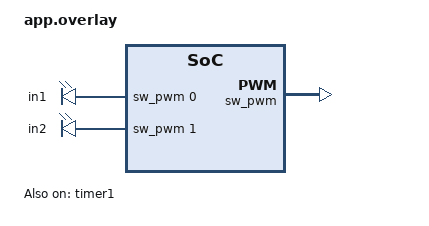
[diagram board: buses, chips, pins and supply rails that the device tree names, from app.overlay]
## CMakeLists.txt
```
# SPDX-License-Identifier: Apache-2.0

cmake_minimum_required(VERSION 3.20.0)
find_package(Zephyr REQUIRED HINTS $ENV{ZEPHYR_BASE})
project(lillabo)

target_sources(app PRIVATE src/main.c)
```

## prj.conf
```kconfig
CONFIG_GPIO=y
CONFIG_UART_CONSOLE=n
# LF clock source is set on the lfclk node in app.overlay; the RC calibration
# it used to need enabling for now defaults to y off that same property.

CONFIG_PWM=y

# From peripheral sample, reduced
CONFIG_BT=y
CONFIG_BT_SMP=y
CONFIG_BT_PERIPHERAL=y
CONFIG_BT_DIS=y
CONFIG_BT_DEVICE_NAME="LILLABOBT"
CONFIG_BT_DEVICE_APPEARANCE=833

# Added from MSLED
CONFIG_BT_RX_STACK_SIZE=1024
CONFIG_BT_HCI_TX_STACK_SIZE_WITH_PROMPT=y
CONFIG_BT_HCI_TX_STACK_SIZE=640
CONFIG_SYSTEM_WORKQUEUE_STACK_SIZE=512
CONFIG_IDLE_STACK_SIZE=64
CONFIG_MAIN_STACK_SIZE=640
CONFIG_ISR_STACK_SIZE=640

# Drivers and peripherals
CONFIG_I2C=n
CONFIG_WATCHDOG=n
CONFIG_SPI=n
CONFIG_SERIAL=n
CONFIG_ADC=n
CONFIG_PINCTRL=y

# Memory protection
CONFIG_THREAD_STACK_INFO=n
CONFIG_THREAD_CUSTOM_DATA=n
CONFIG_FPU=n

# Build
CONFIG_SIZE_OPTIMIZATIONS=y

# ARM
CONFIG_ARM_MPU=n

# Power management
CONFIG_PM=n
 
# Interrupts
CONFIG_DYNAMIC_INTERRUPTS=n
CONFIG_IRQ_OFFLOAD=n

# Disable features not needed
CONFIG_TIMESLICING=n
CONFIG_ASSERT=y

# Disable Bluetooth features not needed
# CONFIG_BT_DEBUG_NONE=y
CONFIG_BT_ASSERT=n
CONFIG_BT_DATA_LEN_UPDATE=n
CONFIG_BT_PHY_UPDATE=n
CONFIG_BT_GATT_CACHING=n
CONFIG_BT_GATT_SERVICE_CHANGED=n
CONFIG_BT_GAP_PERIPHERAL_PREF_PARAMS=n
# CONFIG_BT_HCI_VS_EXT=n

# Disable Bluetooth controller features not needed
CONFIG_BT_CTLR_PRIVACY=n
CONFIG_BT_CTLR_PHY_2M=n

# Reduce Bluetooth buffers
CONFIG_BT_BUF_EVT_DISCARDABLE_COUNT=1
CONFIG_BT_BUF_EVT_DISCARDABLE_SIZE=45
# CONFIG_BT_BUF_ACL_RX_COUNT=2
CONFIG_BT_BUF_EVT_RX_COUNT=2

CONFIG_BT_L2CAP_TX_BUF_COUNT=2
CONFIG_BT_CTLR_RX_BUFFERS=1
CONFIG_BT_BUF_ACL_TX_COUNT=1
CONFIG_BT_BUF_ACL_TX_SIZE=27

# Crypto. The BT controller and host pull in PSA crypto (via mbedtls) whether
# we want it or not; the key slot table is statically sized, and 16 slots is
# far more than a single-connection peripheral uses. Matches the value in
# zephyr/samples/bluetooth/peripheral_hr/prj_minimal.conf.
CONFIG_MBEDTLS_PSA_KEY_SLOT_COUNT=5

# Logging, disable when not debugging
# CONFIG_CONSOLE=n
CONFIG_PRINTK=y
CONFIG_RTT_CONSOLE=y
CONFIG_USE_SEGGER_RTT=y
CONFIG_SEGGER_RTT_BUFFER_SIZE_UP=255
CONFIG_SEGGER_RTT_MAX_NUM_UP_BUFFERS=1
CONFIG_LOG=n
```

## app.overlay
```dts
/ {
	hbridge {
		compatible = "pwm-leds";
		status = "okay";

		in1: in1 {
			pwms = < &sw_pwm 0 PWM_USEC(100) PWM_POLARITY_NORMAL >;
		};

		in2: in2 {
			pwms = < &sw_pwm 1 PWM_USEC(100) PWM_POLARITY_NORMAL >;
		};
	};
};

&sw_pwm {
	status = "okay";
	channel-gpios = < &gpio0 12 GPIO_ACTIVE_HIGH >,
	                < &gpio0 14 GPIO_ACTIVE_HIGH >;
	clock-prescaler = <4>;
};

&timer1 {
	status = "okay";
};

/* Low-frequency clock: run from the internal RC oscillator. This used to be
 * CONFIG_CLOCK_CONTROL_NRF_K32SRC_RC; the accuracy has to be stated explicitly
 * because the binding defaults to 50 ppm, while RC on the nRF52 is 500 ppm and
 * the BLE controller reports this value as its sleep clock accuracy. */
&lfclk {
	k32src = "rc";
	k32src-accuracy-ppm = <500>;
};
```

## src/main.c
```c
/*
 * DRV8212 A/B leg test
 * --------------------
 *
 * DRV8212 IN1/IN2 truth table (logical levels; 1 = pin driven active):
 *
 *   IN1  IN2   Bridge state
 *   ---  ---   -------------------------------------------------
 *    0    0    COAST   - both outputs Hi-Z          (safe idle / baseline)
 *    1    0    FORWARD - OUT1 high-side ON          (exercises leg 1)
 *    0    1    REVERSE - OUT2 high-side ON          (exercises leg 2 = suspect)
 *    1    1    BRAKE   - both low-side ON           (NEVER commanded here)
 *
 * Safety of the test itself:
 *   - We ALWAYS pass through COAST (0,0) between drive states, so the inputs
 *     never transition straight from (1,0) to (0,1). That makes it impossible
 *     to momentarily land on (1,1)=brake or to cross-conduct during the switch.
 *   - REVERSE (the suspect leg) is kept short, and the whole test is bounded
 *     to a few cycles then parked in COAST, so a damaged leg isn't baked
 *     further while you read the trace.
 */

#include <zephyr/drivers/pwm.h>
#include <zephyr/kernel.h>

#include <zephyr/bluetooth/bluetooth.h>
#include <zephyr/bluetooth/conn.h>
#include <zephyr/bluetooth/gatt.h>
#include <zephyr/bluetooth/hci.h>
#include <zephyr/bluetooth/uuid.h>

static const struct pwm_dt_spec in1 = PWM_DT_SPEC_GET(DT_NODELABEL(in1));
static const struct pwm_dt_spec in2 = PWM_DT_SPEC_GET(DT_NODELABEL(in2));

/* Motor control GATT service.
 *
 * Custom 128-bit UUIDs. Random base 0c103c4b-6ae9-47e2-9983-100f660c9654,
 * low byte of the first field varied per attribute:
 *   service  0c103c01-...   primary service
 *   speed    0c103c02-...   uint8, 0-255
 *   mode     0c103c03-...   uint8, see enum motor_mode below
 */
#define BT_UUID_MOTOR_SERVICE_VAL \
	BT_UUID_128_ENCODE(0x0c103c01, 0x6ae9, 0x47e2, 0x9983, 0x100f660c9654)
#define BT_UUID_MOTOR_SERVICE BT_UUID_DECLARE_128(BT_UUID_MOTOR_SERVICE_VAL)

#define BT_UUID_MOTOR_SPEED_VAL \
	BT_UUID_128_ENCODE(0x0c103c02, 0x6ae9, 0x47e2, 0x9983, 0x100f660c9654)
#define BT_UUID_MOTOR_SPEED BT_UUID_DECLARE_128(BT_UUID_MOTOR_SPEED_VAL)

#define BT_UUID_MOTOR_MODE_VAL \
	BT_UUID_128_ENCODE(0x0c103c03, 0x6ae9, 0x47e2, 0x9983, 0x100f660c9654)
#define BT_UUID_MOTOR_MODE BT_UUID_DECLARE_128(BT_UUID_MOTOR_MODE_VAL)

enum motor_mode
{
	MOTOR_FORWARD = 0,
	MOTOR_BACKWARDS,
	MOTOR_COAST,
	MOTOR_BRAKE,
};

static uint8_t motor_speed; /* 0-255 */
static uint8_t motor_mode = MOTOR_COAST;

static const struct bt_data ad[] = {
    BT_DATA_BYTES(BT_DATA_FLAGS, (BT_LE_AD_GENERAL | BT_LE_AD_NO_BREDR)),
    BT_DATA_BYTES(BT_DATA_UUID128_ALL, BT_UUID_MOTOR_SERVICE_VAL),
};

static const struct bt_data sd[] = {
    BT_DATA(BT_DATA_NAME_COMPLETE, CONFIG_BT_DEVICE_NAME, sizeof(CONFIG_BT_DEVICE_NAME) - 1),
};

/* Set the bridge state. We set the pin going to 0 first when leaving a drive
 * state, which keeps every intermediate combination a safe one. */
static int
bridge_set(uint8_t v1, uint8_t v2)
{
	printk("v1=%d,v2=%d\n", v1 * 100000 / 255, v2 * 100000 / 255);
	int ret = pwm_set_pulse_dt(&in1, v1 * 100000 / 255);
	if (ret < 0) {
		return ret;
	}
	return pwm_set_pulse_dt(&in2, v2 * 100000 / 255);
}

/* Apply the current motor state to the hardware. Called whenever the Speed or
 * Mode characteristic is written. Fill this in to drive the H-bridge (e.g. PWM
 * duty from `speed`, direction from `mode` via bridge_set()). */
static void
motor_apply(uint8_t mode, uint8_t speed)
{
	switch (mode) {
	case MOTOR_FORWARD: bridge_set(speed, 0); break;
	case MOTOR_BACKWARDS: bridge_set(0, speed); break;
	case MOTOR_BRAKE: bridge_set(speed, speed); break;
	case MOTOR_COAST: bridge_set(0, 0); break;
	}

	printk("Applied motor settings mode=%d,speed=%02x\n", mode, speed);
}

static ssize_t
read_speed(
    struct bt_conn *conn, const struct bt_gatt_attr *attr, void *buf, uint16_t len, uint16_t offset)
{
	return bt_gatt_attr_read(conn, attr, buf, len, offset, &motor_speed, sizeof(motor_speed));
}

static ssize_t
write_speed(struct bt_conn *conn, const struct bt_gatt_attr *attr, const void *buf, uint16_t len,
    uint16_t offset, uint8_t flags)
{
	if (offset != 0) {
		return BT_GATT_ERR(BT_ATT_ERR_INVALID_OFFSET);
	}
	if (len != sizeof(motor_speed)) {
		return BT_GATT_ERR(BT_ATT_ERR_INVALID_ATTRIBUTE_LEN);
	}

	motor_speed = ((const uint8_t *)buf)[0];
	motor_apply(motor_mode, motor_speed);
	return len;
}

static ssize_t
read_mode(
    struct bt_conn *conn, const struct bt_gatt_attr *attr, void *buf, uint16_t len, uint16_t offset)
{
	return bt_gatt_attr_read(conn, attr, buf, len, offset, &motor_mode, sizeof(motor_mode));
}

static ssize_t
write_mode(struct bt_conn *conn, const struct bt_gatt_attr *attr, const void *buf, uint16_t len,
    uint16_t offset, uint8_t flags)
{
	uint8_t mode;

	if (offset != 0) {
		return BT_GATT_ERR(BT_ATT_ERR_INVALID_OFFSET);
	}
	if (len != sizeof(motor_mode)) {
		return BT_GATT_ERR(BT_ATT_ERR_INVALID_ATTRIBUTE_LEN);
	}

	mode = ((const uint8_t *)buf)[0];
	if (mode > MOTOR_BRAKE) {
		return BT_GATT_ERR(BT_ATT_ERR_VALUE_NOT_ALLOWED);
	}

	motor_mode = mode;
	motor_apply(motor_mode, motor_speed);
	return len;
}

BT_GATT_SERVICE_DEFINE(motor_svc, BT_GATT_PRIMARY_SERVICE(BT_UUID_MOTOR_SERVICE),
    BT_GATT_CHARACTERISTIC(BT_UUID_MOTOR_SPEED, BT_GATT_CHRC_READ | BT_GATT_CHRC_WRITE,
	BT_GATT_PERM_READ | BT_GATT_PERM_WRITE, read_speed, write_speed, &motor_speed),
    BT_GATT_CHARACTERISTIC(BT_UUID_MOTOR_MODE, BT_GATT_CHRC_READ | BT_GATT_CHRC_WRITE,
	BT_GATT_PERM_READ | BT_GATT_PERM_WRITE, read_mode, write_mode, &motor_mode), );

static int
start_adv(void)
{
	int ret = bt_le_adv_start(BT_LE_ADV_CONN_FAST_1, ad, ARRAY_SIZE(ad), sd, ARRAY_SIZE(sd));
	if (ret) {
		printk("Advertising failed to start (%d)\n", ret);
	}
	return ret;
}

/* Restart advertising off the system workqueue: starting connectable adv
 * directly from the disconnected callback fails with -ENOMEM because the
 * just-closed connection slot is not freed until the callback returns. */
static void
adv_work_handler(struct k_work *work)
{
	start_adv();
}

static K_WORK_DEFINE(adv_work, adv_work_handler);

static void
connected(struct bt_conn *conn, uint8_t err)
{
	if (err) {
		printk("Connection failed, err 0x%02x %s\n", err, bt_hci_err_to_str(err));
	} else {
		printk("Connected\n");
	}
}

static void
disconnected(struct bt_conn *conn, uint8_t reason)
{
	printk("Disconnected, reason 0x%02x %s\n", reason, bt_hci_err_to_str(reason));
	k_work_submit(&adv_work);
}

BT_CONN_CB_DEFINE(conn_callbacks) = {
    .connected = connected,
    .disconnected = disconnected,
};

static void
auth_passkey_display(struct bt_conn *conn, unsigned int passkey)
{
	printk("Passkey for %s: %06u\n", bt_conn_dst_str(conn), passkey);
}

static void
auth_cancel(struct bt_conn *conn)
{
	printk("Pairing cancelled: %s\n", bt_conn_dst_str(conn));
}

void
mtu_updated(struct bt_conn *conn, uint16_t tx, uint16_t rx)
{
	printk("Updated MTU: TX: %d RX: %d bytes\n", tx, rx);
}

static struct bt_gatt_cb gatt_callbacks = {.att_mtu_updated = mtu_updated};

static struct bt_conn_auth_cb auth_cb_display = {
    .passkey_display = auth_passkey_display,
    .passkey_entry = NULL,
    .cancel = auth_cancel,
};

static int
init_bt(void)
{
	int ret;
	ret = bt_enable(NULL);
	if (ret) {
		printk("Bluetooth init failed (%d)\n", ret);
		return ret;
	}

	start_adv();

	bt_conn_auth_cb_register(&auth_cb_display);
	bt_gatt_cb_register(&gatt_callbacks);

	printk("Advertising successfully started\n");

	return 0;
}

int
main(void)
{
	int ret;

	bridge_set(0, 0);

	ret = init_bt();
	if (ret) {
		printk("ERROR: Bluetooth setup failed (%d)\n", ret);
		return 0;
	}

	while (1) {
		k_msleep(1000);
	}
	return 0;
}
```
